# CY8C5888LTI_LP097 register map
File version: 0.1
Registers are 8-bit, read-write, no defined reset value unless marked. A register's access mark holds for its fields unless they carry their own. Offsets are from the block's base; [hi:lo] are bit positions; 'fields as' and 'values as' point back to an identical list.

## RTC
Base 0x00000000
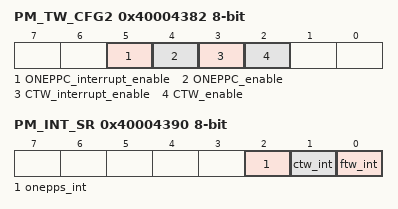
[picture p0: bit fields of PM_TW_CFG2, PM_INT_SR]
0x40004382 PM_TW_CFG2 — Power timers enable and interrupt enable configuration register
  [5] ONEPPC_interrupt_enable — When set and one pulse-per-second is enabled, an interrupt is issued when the pulse occurs
    1=Enabled (The ONEPPC interrupt is issued. Only if ONEPPC is enabled.); 0=Disabled (No ONEPPC interrupt is issued.)
  [4] ONEPPC_enable
    1=Enabled (The ONEPPC is enabled.); 0=Disabled (The ONEPPC is disabled.)
  [3] CTW_interrupt_enable — An interrupt issue when the CTW reaches the selected interval
    1=Enabled (The CTW interrupt is issued. Only if CTW is enabled.); 0=Disabled (No CTW interrupt is issued.)
  [2] CTW_enable
    1=Enabled (The CTW is enabled.); 0=Disabled (The CTW is disabled.)
0x40004390 PM_INT_SR — Power Manager Interrupt Status Register
  [2] onepps_int — When set, a onepps event has occured.
  [1] ctw_int — When set, a limited active ready event has occured
  [0] ftw_int — When set, a fast timewheel event has occured

## Control_Reg_1
Base 0x00000000
0x4000647C Control_Reg_1_CONTROL_REG

## Timer_R2
Base 0x00000000
0x4000640C Timer_R2_COUNTER 16-bit — UDB.A0 - Current Down Counter Value
0x4000642C Timer_R2_PERIOD 16-bit — UDB.D0 - Assigned Period
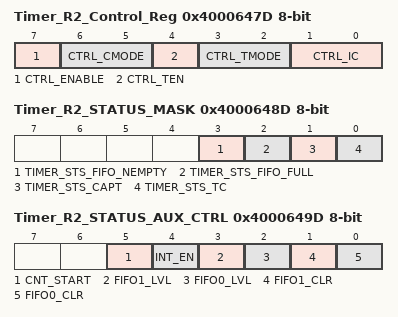
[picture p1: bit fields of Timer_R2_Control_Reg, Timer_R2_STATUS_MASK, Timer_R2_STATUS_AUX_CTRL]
0x4000647D Timer_R2_Control_Reg — UDB Control Register - Assigned Control Register Value
  [7] CTRL_ENABLE — Enable the Timer
  [6:5] CTRL_CMODE — Capture Mode
  [4] CTRL_TEN — Trigger Enable Bit
  [3:2] CTRL_TMODE — Trigger Mode
  [1:0] CTRL_IC — Interrupt Count
0x4000648D Timer_R2_STATUS_MASK — UDB Status bits Interrupt Mask Enable Register
  [3] TIMER_STS_FIFO_NEMPTY ro — FIFO Empty status
  [2] TIMER_STS_FIFO_FULL ro — FIFO Full Status
  [1] TIMER_STS_CAPT ro — Enables the Interrupt on Capture
  [0] TIMER_STS_TC ro — Enables the Interrupt on TC
0x4000649D Timer_R2_STATUS_AUX_CTRL — UDB Auxilliary Control Register
  [5] CNT_START — FIFO0 clear
    0=E_CNT_START0 (Disable counter); 1=E_CNT_START1 (Enable counter)
  [4] INT_EN
    0=E_INT_EN0 (Interrupt disabled); 1=E_INT_EN1 (Interrupt enabled)
  [3] FIFO1_LVL — FIFO level
    0=E_FIFO_LVL_0 (FIFO LVL: input mode: FIFO not full; output mode: FIFO not empty); 1=E_FIFO_LVL_1 (FIFO LVL: input mode: FIFO at least 1/2 empty; output mode: FIFO at least 1/2 full)
  [2] FIFO0_LVL — FIFO level
    values as FIFO1_LVL
  [1] FIFO1_CLR — FIFO1 clear
    0=E_FIFO_CLR_0 (Normal FIFO operation); 1=E_FIFO_CLR_1 (Clear FIFO state)
  [0] FIFO0_CLR — FIFO0 clear
    values as FIFO1_CLR

## Timer_L2
Base 0x00000000
0x4000640A Timer_L2_COUNTER 16-bit — UDB.A0 - Current Down Counter Value
0x4000642A Timer_L2_PERIOD 16-bit — UDB.D0 - Assigned Period
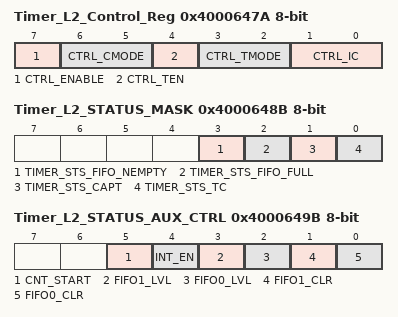
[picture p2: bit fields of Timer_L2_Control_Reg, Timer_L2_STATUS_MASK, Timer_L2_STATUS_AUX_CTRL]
0x4000647A Timer_L2_Control_Reg — UDB Control Register - Assigned Control Register Value
  [7] CTRL_ENABLE — Enable the Timer
  [6:5] CTRL_CMODE — Capture Mode
  [4] CTRL_TEN — Trigger Enable Bit
  [3:2] CTRL_TMODE — Trigger Mode
  [1:0] CTRL_IC — Interrupt Count
0x4000648B Timer_L2_STATUS_MASK — UDB Status bits Interrupt Mask Enable Register
  [3] TIMER_STS_FIFO_NEMPTY ro — FIFO Empty status
  [2] TIMER_STS_FIFO_FULL ro — FIFO Full Status
  [1] TIMER_STS_CAPT ro — Enables the Interrupt on Capture
  [0] TIMER_STS_TC ro — Enables the Interrupt on TC
0x4000649B Timer_L2_STATUS_AUX_CTRL — UDB Auxilliary Control Register
  [5] CNT_START — FIFO0 clear
    0=E_CNT_START0 (Disable counter); 1=E_CNT_START1 (Enable counter)
  [4] INT_EN
    0=E_INT_EN0 (Interrupt disabled); 1=E_INT_EN1 (Interrupt enabled)
  [3] FIFO1_LVL — FIFO level
    0=E_FIFO_LVL_0 (FIFO LVL: input mode: FIFO not full; output mode: FIFO not empty); 1=E_FIFO_LVL_1 (FIFO LVL: input mode: FIFO at least 1/2 empty; output mode: FIFO at least 1/2 full)
  [2] FIFO0_LVL — FIFO level
    values as FIFO1_LVL
  [1] FIFO1_CLR — FIFO1 clear
    0=E_FIFO_CLR_0 (Normal FIFO operation); 1=E_FIFO_CLR_1 (Clear FIFO state)
  [0] FIFO0_CLR — FIFO0 clear
    values as FIFO1_CLR
